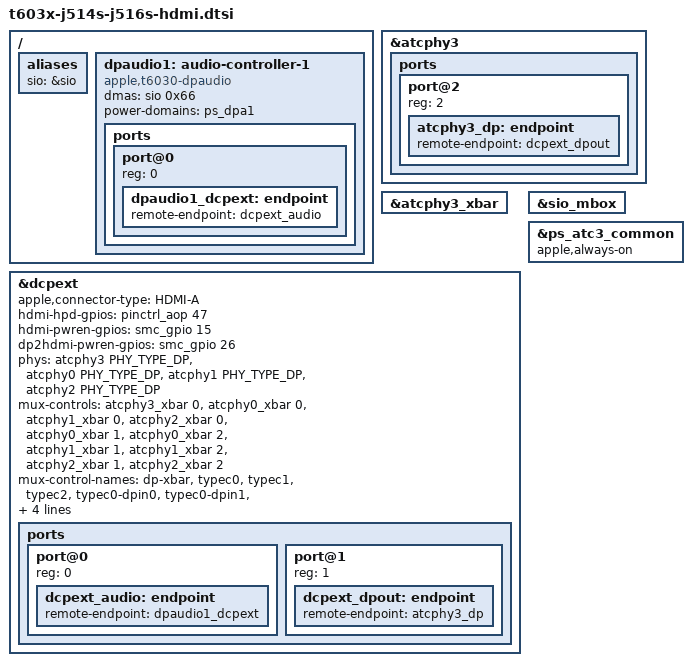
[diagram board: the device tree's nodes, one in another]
// SPDX-License-Identifier: GPL-2.0+ OR MIT
/*
 * HDMI port of the T6030 (M3 Pro) J514S and J516S: dcpext drives ATC3 as a
 * four-lane DP PHY into a DP-to-HDMI converter, as on the M1/M2 Pro and Max
 * MacBook Pros, and can still lend itself to a USB-C port. Its audio is DPA1
 * on SIO channel 0x66.
 */

/ {
	aliases {
		/* The boot loader looks the SIO up by this alias. */
		sio = &sio;
	};
};

&atcphy3 {
	status = "okay";

	ports {
		#address-cells = <1>;
		#size-cells = <0>;

		port@2 {
			reg = <2>;
			atcphy3_dp: endpoint {
				remote-endpoint = <&dcpext_dpout>;
			};
		};
	};
};

&atcphy3_xbar {
	status = "okay";
};

&dcpext {
	apple,connector-type = "HDMI-A";

	/* HDMI HPD, also used as the hotplug interrupt */
	hdmi-hpd-gpios = <&pinctrl_aop 47 GPIO_ACTIVE_HIGH>;
	hdmi-pwren-gpios = <&smc_gpio 15 GPIO_ACTIVE_HIGH>;
	dp2hdmi-pwren-gpios = <&smc_gpio 26 GPIO_ACTIVE_HIGH>;

	phys = <&atcphy3 PHY_TYPE_DP>, <&atcphy0 PHY_TYPE_DP>,
	       <&atcphy1 PHY_TYPE_DP>, <&atcphy2 PHY_TYPE_DP>;
	phy-names = "dp-phy", "typec0", "typec1", "typec2";
	mux-controls = <&atcphy3_xbar 0>, <&atcphy0_xbar 0>,
		       <&atcphy1_xbar 0>, <&atcphy2_xbar 0>,
		       <&atcphy0_xbar 1>, <&atcphy0_xbar 2>,
		       <&atcphy1_xbar 1>, <&atcphy1_xbar 2>,
		       <&atcphy2_xbar 1>, <&atcphy2_xbar 2>;
	mux-control-names = "dp-xbar", "typec0", "typec1", "typec2",
			    "typec0-dpin0", "typec0-dpin1",
			    "typec1-dpin0", "typec1-dpin1",
			    "typec2-dpin0", "typec2-dpin1";
	mux-index = <0>;
	apple,dptx-phy = <3>;

	ports {
		#address-cells = <1>;
		#size-cells = <0>;

		port@0 {
			reg = <0>;
			dcpext_audio: endpoint {
				remote-endpoint = <&dpaudio1_dcpext>;
			};
		};

		port@1 {
			reg = <1>;
			dcpext_dpout: endpoint {
				remote-endpoint = <&atcphy3_dp>;
			};
		};
	};
};

/* DPA1 has no AP-side registers, so it is not a child of the SoC bus. */
/ {
	dpaudio1: audio-controller-1 {
		compatible = "apple,t6030-dpaudio", "apple,dpaudio";
		dmas = <&sio 0x66>;
		dma-names = "tx";
		power-domains = <&ps_dpa1>;

		ports {
			#address-cells = <1>;
			#size-cells = <0>;

			port@0 {
				reg = <0>;
				dpaudio1_dcpext: endpoint {
					remote-endpoint = <&dcpext_audio>;
				};
			};
		};
	};
};

/* The SIO's mailbox; the boot loader enables the SIO with its firmware. */
&sio_mbox {
	status = "okay";
};

/* Nothing else holds ATC3 on across sleep, which loses the PHY state. */
&ps_atc3_common {
	apple,always-on;
};
